# nrf52820 register map
Vendor: Nordic Semiconductor; Series: nrf52; File version: 1
CPU: CM4 r0p1, little endian, MPU, no FPU, 3 interrupt priority bits
Registers are 32-bit, read-write, reset 0x0 unless marked. A register's access mark holds for its fields unless they carry their own. Offsets are from the block's base; [hi:lo] are bit positions; 'fields as' and 'values as' point back to an identical list.

## RNG — Random Number Generator
Base 0x4000D000
0x00 TASKS_START wo — Task starting the random number generator
  [0] TASKS_START
    1=Trigger task
0x04 TASKS_STOP wo — Task stopping the random number generator
  [0] TASKS_STOP
    1=Trigger task
0x100 EVENTS_VALRDY — Event being generated for every new random number written to the VALUE register
  [0] EVENTS_VALRDY
    0=NotGenerated (Event not generated); 1=Generated (Event generated)
0x200 SHORTS — Shortcuts between local events and tasks
  [0] VALRDY_STOP — Shortcut between event VALRDY and task STOP
    0=Disabled (Disable shortcut); 1=Enabled (Enable shortcut)
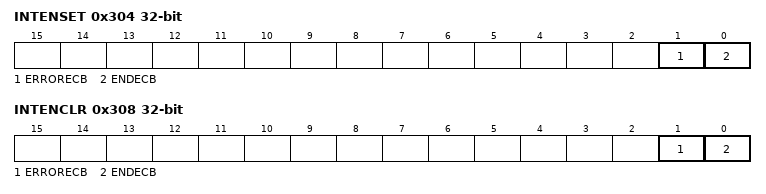
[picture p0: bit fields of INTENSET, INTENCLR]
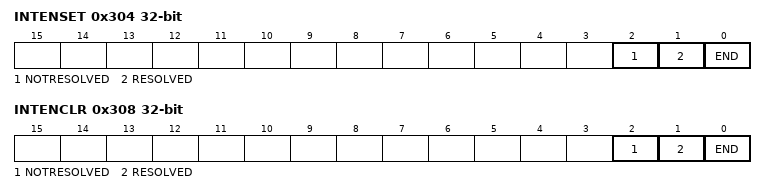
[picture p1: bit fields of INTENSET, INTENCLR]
0x304 INTENSET — Enable interrupt
  [0] VALRDY — Write '1' to enable interrupt for event VALRDY
    on read: 0=Disabled (Read: Disabled); 1=Enabled (Read: Enabled) | on write: 1=Set (Enable)
0x308 INTENCLR — Disable interrupt
  [0] VALRDY — Write '1' to disable interrupt for event VALRDY
    on read: 0=Disabled (Read: Disabled); 1=Enabled (Read: Enabled) | on write: 1=Clear (Disable)
0x504 CONFIG — Configuration register
  [0] DERCEN — Bias correction
    0=Disabled; 1=Enabled
0x508 VALUE ro — Output random number
  [7:0] VALUE — Generated random number

## ECB — AES ECB Mode Encryption
Base 0x4000E000
0x00 TASKS_STARTECB wo — Start ECB block encrypt
  [0] TASKS_STARTECB
    1=Trigger task
0x04 TASKS_STOPECB wo — Abort a possible executing ECB operation
  [0] TASKS_STOPECB
    1=Trigger task
0x100 EVENTS_ENDECB — ECB block encrypt complete
  [0] EVENTS_ENDECB
    0=NotGenerated (Event not generated); 1=Generated (Event generated)
0x104 EVENTS_ERRORECB — ECB block encrypt aborted because of a STOPECB task or due to an error
  [0] EVENTS_ERRORECB
    values as EVENTS_ENDECB.EVENTS_ENDECB
0x304 INTENSET — Enable interrupt
  [1] ERRORECB — Write '1' to enable interrupt for event ERRORECB
    on read: 0=Disabled (Read: Disabled); 1=Enabled (Read: Enabled) | on write: 1=Set (Enable)
  [0] ENDECB — Write '1' to enable interrupt for event ENDECB
    values as ERRORECB
0x308 INTENCLR — Disable interrupt
  [1] ERRORECB — Write '1' to disable interrupt for event ERRORECB
    on read: 0=Disabled (Read: Disabled); 1=Enabled (Read: Enabled) | on write: 1=Clear (Disable)
  [0] ENDECB — Write '1' to disable interrupt for event ENDECB
    values as ERRORECB
0x504 ECBDATAPTR — ECB block encrypt memory pointers
  [31:0] ECBDATAPTR — Pointer to the ECB data structure (see Table 1 ECB data structure overview)

## AAR — Accelerated Address Resolver
Base 0x4000F000
0x00 TASKS_START wo — Start resolving addresses based on IRKs specified in the IRK data structure
  [0] TASKS_START
    1=Trigger task
0x08 TASKS_STOP wo — Stop resolving addresses
  [0] TASKS_STOP
    1=Trigger task
0x100 EVENTS_END — Address resolution procedure complete
  [0] EVENTS_END
    0=NotGenerated (Event not generated); 1=Generated (Event generated)
0x104 EVENTS_RESOLVED — Address resolved
  [0] EVENTS_RESOLVED
    values as EVENTS_END.EVENTS_END
0x108 EVENTS_NOTRESOLVED — Address not resolved
  [0] EVENTS_NOTRESOLVED
    values as EVENTS_END.EVENTS_END
0x304 INTENSET — Enable interrupt
  [all] fields
    on read: 0=Disabled (Read: Disabled); 1=Enabled (Read: Enabled) | on write: 1=Set (Enable)
  [2] NOTRESOLVED — Write '1' to enable interrupt for event NOTRESOLVED
  [1] RESOLVED — Write '1' to enable interrupt for event RESOLVED
  [0] END — Write '1' to enable interrupt for event END
0x308 INTENCLR — Disable interrupt
  [all] fields
    on read: 0=Disabled (Read: Disabled); 1=Enabled (Read: Enabled) | on write: 1=Clear (Disable)
  [2] NOTRESOLVED — Write '1' to disable interrupt for event NOTRESOLVED
  [1] RESOLVED — Write '1' to disable interrupt for event RESOLVED
  [0] END — Write '1' to disable interrupt for event END
0x400 STATUS ro — Resolution status
  [3:0] STATUS — The IRK that was used last time an address was resolved
0x500 ENABLE — Enable AAR
  [1:0] ENABLE — Enable or disable AAR
    0=Disabled; 3=Enabled
0x504 NIRK reset 0x1 — Number of IRKs
  [4:0] NIRK — Number of Identity Root Keys available in the IRK data structure
0x508 IRKPTR — Pointer to IRK data structure
  [31:0] IRKPTR — Pointer to the IRK data structure
0x510 ADDRPTR — Pointer to the resolvable address
  [31:0] ADDRPTR — Pointer to the resolvable address (6-bytes)
0x514 SCRATCHPTR — Pointer to data area used for temporary storage
  [31:0] SCRATCHPTR — Pointer to a scratch data area used for temporary storage during resolution. A space of minimum 3 bytes must be reserved.

## Notices in the file
Copyright (c) 2010 - 2024, Nordic Semiconductor ASA
All rights reserved.
Redistribution and use in source and binary forms, with or without modification,
are permitted provided that the following conditions are met:
1. Redistributions of source code must retain the above copyright notice, this
list of conditions and the following disclaimer.
2. Redistributions in binary form, except as embedded into a Nordic
Semiconductor ASA integrated circuit in a product or a software update for
such product, must reproduce the above copyright notice, this list of
conditions and the following disclaimer in the documentation and/or other
materials provided with the distribution.
3. Neither the name of Nordic Semiconductor ASA nor the names of its
contributors may be used to endorse or promote products derived from this
software without specific prior written permission.
4. This software, with or without modification, must only be used with a
Nordic Semiconductor ASA integrated circuit.
5. Any software provided in binary form under this license must not be reverse
engineered, decompiled, modified and/or disassembled.
THIS SOFTWARE IS PROVIDED BY NORDIC SEMICONDUCTOR ASA "AS IS" AND ANY EXPRESS
OR IMPLIED WARRANTIES, INCLUDING, BUT NOT LIMITED TO, THE IMPLIED WARRANTIES
OF MERCHANTABILITY, NONINFRINGEMENT, AND FITNESS FOR A PARTICULAR PURPOSE ARE
DISCLAIMED. IN NO EVENT SHALL NORDIC SEMICONDUCTOR ASA OR CONTRIBUTORS BE
LIABLE FOR ANY DIRECT, INDIRECT, INCIDENTAL, SPECIAL, EXEMPLARY, OR
CONSEQUENTIAL DAMAGES (INCLUDING, BUT NOT LIMITED TO, PROCUREMENT OF SUBSTITUTE
GOODS OR SERVICES; LOSS OF USE, DATA, OR PROFITS; OR BUSINESS INTERRUPTION)
HOWEVER CAUSED AND ON ANY THEORY OF LIABILITY, WHETHER IN CONTRACT, STRICT
LIABILITY, OR TORT (INCLUDING NEGLIGENCE OR OTHERWISE) ARISING IN ANY WAY OUT
OF THE USE OF THIS SOFTWARE, EVEN IF ADVISED OF THE POSSIBILITY OF SUCH DAMAGE.
